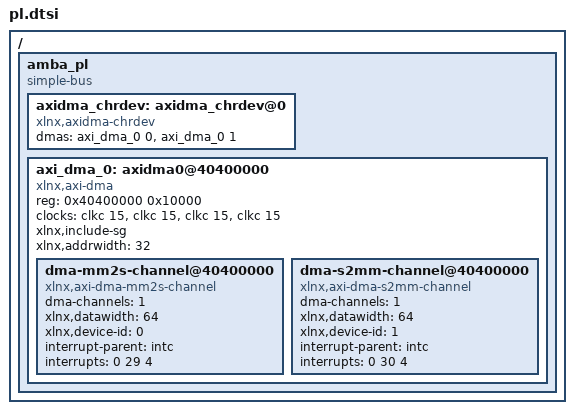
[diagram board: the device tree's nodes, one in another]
/*
 * CAUTION: This file is automatically generated by Xilinx.
 * Version:  
 * Today is: Thu Nov 16 09:32:20 2017
*/


/ {
	amba_pl: amba_pl {
		#address-cells = <1>;
		#size-cells = <1>;
		compatible = "simple-bus";
		ranges ;
    axidma_chrdev: axidma_chrdev@0 {
    compatible = "xlnx,axidma-chrdev";
    dmas = <&axi_dma_0 0 &axi_dma_0 1>;
    dma-names = "tx_channel", "rx_channel";
};
		axi_dma_0: axidma0@40400000 {
    #dma-cells = <1>;
    compatible = "xlnx,axi-dma", "xlnx,axi-dma-6.03.a", "xlnx,axi-dma-1.00.a";
    reg = <0x40400000 0x10000>;
    clocks = <&clkc 15>, <&clkc 15>, <&clkc 15>, <&clkc 15>;
    clock-names = "s_axi_lite_aclk", "m_axi_sg_aclk", "m_axi_mm2s_aclk",
"m_axi_s2mm_aclk";    
    xlnx,include-sg;    
    xlnx,addrwidth = <32>;

    dma-mm2s-channel@40400000 {
        compatible = "xlnx,axi-dma-mm2s-channel";
        dma-channels = <1>;
        xlnx,datawidth = <64>;
        xlnx,device-id = <0>;
        interrupt-parent = <&intc>;
        interrupts = <0 29 4>;
    };
    
    dma-s2mm-channel@40400000 {
        compatible = "xlnx,axi-dma-s2mm-channel";
        dma-channels = <1>;
        xlnx,datawidth = <64>;
        xlnx,device-id = <1>;
        interrupt-parent = <&intc>;
        interrupts = <0 30 4>;
    };
};
	};
};
